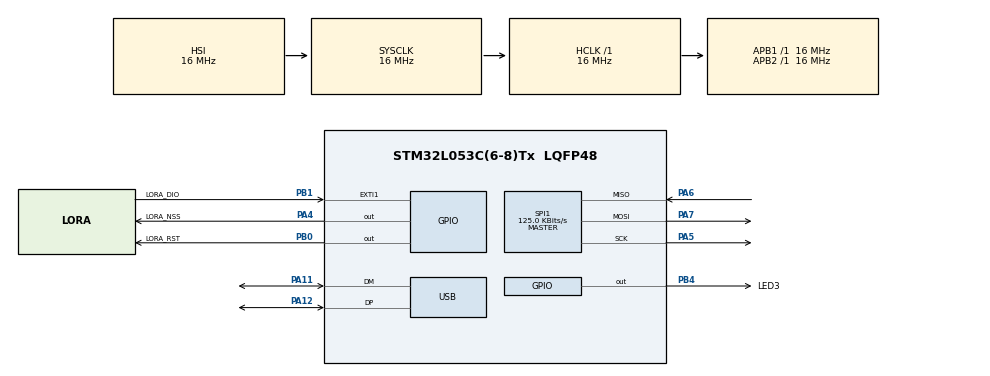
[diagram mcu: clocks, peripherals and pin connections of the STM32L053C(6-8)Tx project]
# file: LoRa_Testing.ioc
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Mcu.Family=STM32L0
Mcu.Name=STM32L053C(6-8)Tx
Mcu.Package=LQFP48
NVIC.EXTI0_1_IRQn=true\:0\:0\:false\:false\:true\:true\:true
NVIC.USB_IRQn=true\:0\:0\:false\:false\:true\:true\:true
PA11.Mode=Device
PA11.Signal=USB_DM
PA12.Mode=Device
PA12.Signal=USB_DP
PA4.GPIO_Label=LORA_NSS
PA4.PinState=GPIO_PIN_SET
PA4.Signal=GPIO_Output
PA5.Mode=Full_Duplex_Master
PA5.Signal=SPI1_SCK
PA6.Mode=Full_Duplex_Master
PA6.Signal=SPI1_MISO
PA7.Mode=Full_Duplex_Master
PA7.Signal=SPI1_MOSI
PB0.GPIO_Label=LORA_RST
PB0.PinState=GPIO_PIN_SET
PB0.Signal=GPIO_Output
PB1.GPIO_Label=LORA_DIO
PB1.GPIO_ModeDefaultEXTI=GPIO_MODE_IT_RISING
PB1.Signal=GPXTI1
PB4.GPIO_Label=LED3
PB4.Signal=GPIO_Output
ProjectManager.HeapSize=0x200
ProjectManager.StackSize=0x400
ProjectManager.TargetToolchain=TrueSTUDIO
RCC.AHBFreq_Value=16000000
RCC.APB1Freq_Value=16000000
RCC.APB1TimFreq_Value=16000000
RCC.APB2Freq_Value=16000000
RCC.APB2TimFreq_Value=16000000
RCC.HCLKFreq_Value=16000000
RCC.HSE_VALUE=8000000
RCC.HSI16_VALUE=16000000
RCC.HSI48MClockSelection=RCC_USBCLKSOURCE_HSI48
RCC.HSI48_VALUE=48000000
RCC.HSI_VALUE=16000000
RCC.LSE_VALUE=32768
RCC.MSI_VALUE=2097000
RCC.PLLMUL=RCC_PLLMUL_6
RCC.SYSCLKFreq_VALUE=16000000
RCC.SYSCLKSource=RCC_SYSCLKSOURCE_HSI
RCC.VCOOutputFreq_Value=96000000
SPI1.BaudRatePrescaler=SPI_BAUDRATEPRESCALER_128
SPI1.CalculateBaudRate=125.0 KBits/s
SPI1.Direction=SPI_DIRECTION_2LINES
SPI1.Mode=SPI_MODE_MASTER
SPI1.VirtualType=VM_MASTER
USB_DEVICE.CLASS_NAME_FS=CDC
USB_DEVICE.VirtualMode=Cdc
USB_DEVICE.VirtualModeFS=Cdc_FS
VP_USB_DEVICE_VS_USB_DEVICE_CDC_FS.Mode=CDC_FS
board=custom

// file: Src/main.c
/* USER CODE BEGIN Header */
/**
  ******************************************************************************
  * @file           : main.c
  * @brief          : Main program body
  ******************************************************************************
  * @attention
  *
  * <h2><center>&copy; Copyright (c) 2020 STMicroelectronics.
  * All rights reserved.</center></h2>
  *
  * This software component is licensed by ST under BSD 3-Clause license,
  * the "License"; You may not use this file except in compliance with the
  * License. You may obtain a copy of the License at:
  *                        opensource.org/licenses/BSD-3-Clause
  *
  ******************************************************************************
  */
/* USER CODE END Header */

#include "main.h"
#include "usb_device.h"

/* USER CODE BEGIN Includes */
#include "lora.h"
/* USER CODE END Includes */

SPI_HandleTypeDef hspi1;

extern uint8_t receive[80];

void SystemClock_Config(void);
static void MX_GPIO_Init(void);
static void MX_SPI1_Init(void);

/* USER CODE BEGIN 0 */
//uint8_t send[] = "Hello Jacob";

/* USER CODE END 0 */

int main(void)
{

  /* MCU Configuration--------------------------------------------------------*/

  /* Reset of all peripherals, Initializes the Flash interface and the Systick. */
  HAL_Init();

  /* Configure the system clock */
  SystemClock_Config();

  /* Initialize all configured peripherals */
  MX_GPIO_Init();
  MX_SPI1_Init();
  MX_USB_DEVICE_Init();
  /* USER CODE BEGIN 2 */

  LORA_INIT();

  /*
  sendPacket(send, sizeof(send));
  HAL_Delay(1000);
  sendPacket(send1, sizeof(send1));
  HAL_Delay(1000);
  sendPacket(send2, sizeof(send2));
  HAL_Delay(1000);
  sendPacket(send3, sizeof(send3));
  HAL_Delay(1000);
  */

  /* USER CODE END 2 */

  /* Infinite loop */
  /* USER CODE BEGIN WHILE */
  while (1)
  {
	  uint8_t test[] = "x,1,100,100,1000,NW\r\n";
	  sendPacket(test,sizeof(test));
	  HAL_Delay(1000);

	  /*
	  if(readReg(RH_RF95_REG_12_IRQ_FLAGS) == 0x50)
	  {
		  writeReg(RH_RF95_REG_01_OP_MODE, 0x01);
		  writeReg(RH_RF95_REG_12_IRQ_FLAGS, 0xFF);

		  receiveData();

		  writeReg(RH_RF95_REG_01_OP_MODE, 0x05);
		  writeReg(RH_RF95_REG_40_DIO_MAPPING1, 0x00);

		  HAL_GPIO_WritePin(LED3_GPIO_Port, LED3_Pin, GPIO_PIN_SET);
		  HAL_Delay(100);
		  HAL_GPIO_WritePin(LED3_GPIO_Port, LED3_Pin, GPIO_PIN_RESET);
	  }
	*/

    /* USER CODE END WHILE */

  }
}

void SystemClock_Config(void)
{
  RCC_OscInitTypeDef RCC_OscInitStruct = {0};
  RCC_ClkInitTypeDef RCC_ClkInitStruct = {0};
  RCC_PeriphCLKInitTypeDef PeriphClkInit = {0};

  /** Configure the main internal regulator output voltage
  */
  __HAL_PWR_VOLTAGESCALING_CONFIG(PWR_REGULATOR_VOLTAGE_SCALE1);
  /** Initializes the CPU, AHB and APB busses clocks
  */
  RCC_OscInitStruct.OscillatorType = RCC_OSCILLATORTYPE_HSI|RCC_OSCILLATORTYPE_HSI48;
  RCC_OscInitStruct.HSIState = RCC_HSI_ON;
  RCC_OscInitStruct.HSICalibrationValue = RCC_HSICALIBRATION_DEFAULT;
  RCC_OscInitStruct.HSI48State = RCC_HSI48_ON;
  RCC_OscInitStruct.PLL.PLLState = RCC_PLL_NONE;
  if (HAL_RCC_OscConfig(&RCC_OscInitStruct) != HAL_OK)
  {
    Error_Handler();
  }
  /** Initializes the CPU, AHB and APB busses clocks
  */
  RCC_ClkInitStruct.ClockType = RCC_CLOCKTYPE_HCLK|RCC_CLOCKTYPE_SYSCLK
                              |RCC_CLOCKTYPE_PCLK1|RCC_CLOCKTYPE_PCLK2;
  RCC_ClkInitStruct.SYSCLKSource = RCC_SYSCLKSOURCE_HSI;
  RCC_ClkInitStruct.AHBCLKDivider = RCC_SYSCLK_DIV1;
  RCC_ClkInitStruct.APB1CLKDivider = RCC_HCLK_DIV1;
  RCC_ClkInitStruct.APB2CLKDivider = RCC_HCLK_DIV1;

  if (HAL_RCC_ClockConfig(&RCC_ClkInitStruct, FLASH_LATENCY_0) != HAL_OK)
  {
    Error_Handler();
  }
  PeriphClkInit.PeriphClockSelection = RCC_PERIPHCLK_USB;
  PeriphClkInit.UsbClockSelection = RCC_USBCLKSOURCE_HSI48;
  if (HAL_RCCEx_PeriphCLKConfig(&PeriphClkInit) != HAL_OK)
  {
    Error_Handler();
  }
}

static void MX_SPI1_Init(void)
{

  /* SPI1 parameter configuration*/
  hspi1.Instance = SPI1;
  hspi1.Init.Mode = SPI_MODE_MASTER;
  hspi1.Init.Direction = SPI_DIRECTION_2LINES;
  hspi1.Init.DataSize = SPI_DATASIZE_8BIT;
  hspi1.Init.CLKPolarity = SPI_POLARITY_LOW;
  hspi1.Init.CLKPhase = SPI_PHASE_1EDGE;
  hspi1.Init.NSS = SPI_NSS_SOFT;
  hspi1.Init.BaudRatePrescaler = SPI_BAUDRATEPRESCALER_128;
  hspi1.Init.FirstBit = SPI_FIRSTBIT_MSB;
  hspi1.Init.TIMode = SPI_TIMODE_DISABLE;
  hspi1.Init.CRCCalculation = SPI_CRCCALCULATION_DISABLE;
  hspi1.Init.CRCPolynomial = 7;
  if (HAL_SPI_Init(&hspi1) != HAL_OK)
  {
    Error_Handler();
  }

}

static void MX_GPIO_Init(void)
{
  GPIO_InitTypeDef GPIO_InitStruct = {0};

  /* GPIO Ports Clock Enable */
  __HAL_RCC_GPIOA_CLK_ENABLE();
  __HAL_RCC_GPIOB_CLK_ENABLE();

  /*Configure GPIO pin Output Level */
  HAL_GPIO_WritePin(LORA_NSS_GPIO_Port, LORA_NSS_Pin, GPIO_PIN_SET);

  /*Configure GPIO pin Output Level */
  HAL_GPIO_WritePin(LORA_RST_GPIO_Port, LORA_RST_Pin, GPIO_PIN_SET);

  /*Configure GPIO pin Output Level */
  HAL_GPIO_WritePin(LED3_GPIO_Port, LED3_Pin, GPIO_PIN_RESET);

  /*Configure GPIO pin : LORA_NSS_Pin */
  GPIO_InitStruct.Pin = LORA_NSS_Pin;
  GPIO_InitStruct.Mode = GPIO_MODE_OUTPUT_PP;
  GPIO_InitStruct.Pull = GPIO_NOPULL;
  GPIO_InitStruct.Speed = GPIO_SPEED_FREQ_LOW;
  HAL_GPIO_Init(LORA_NSS_GPIO_Port, &GPIO_InitStruct);

  /*Configure GPIO pins : LORA_RST_Pin LED3_Pin */
  GPIO_InitStruct.Pin = LORA_RST_Pin|LED3_Pin;
  GPIO_InitStruct.Mode = GPIO_MODE_OUTPUT_PP;
  GPIO_InitStruct.Pull = GPIO_NOPULL;
  GPIO_InitStruct.Speed = GPIO_SPEED_FREQ_LOW;
  HAL_GPIO_Init(GPIOB, &GPIO_InitStruct);

  /*Configure GPIO pin : LORA_DIO_Pin */
  GPIO_InitStruct.Pin = LORA_DIO_Pin;
  GPIO_InitStruct.Mode = GPIO_MODE_IT_RISING;
  GPIO_InitStruct.Pull = GPIO_NOPULL;
  HAL_GPIO_Init(LORA_DIO_GPIO_Port, &GPIO_InitStruct);

  /* EXTI interrupt init*/
  HAL_NVIC_SetPriority(EXTI0_1_IRQn, 0, 0);
  HAL_NVIC_EnableIRQ(EXTI0_1_IRQn);

}

/* USER CODE BEGIN 4 */
void HAL_GPIO_EXTI_Callback(uint16_t GPIO_Pin){

	HAL_NVIC_DisableIRQ(EXTI0_1_IRQn);

	if(readReg(RH_RF95_REG_12_IRQ_FLAGS) == 0x50)
	  {
		  receiveData();
		  CDC_Transmit_FS(receive, sizeof(receive));

		  //HAL_GPIO_WritePin(LED3_GPIO_Port, LED3_Pin, GPIO_PIN_SET);
		  //HAL_Delay(100);
		  //HAL_GPIO_WritePin(LED3_GPIO_Port, LED3_Pin, GPIO_PIN_RESET);
	  }

	HAL_NVIC_EnableIRQ(EXTI0_1_IRQn);

}
/* USER CODE END 4 */

void Error_Handler(void)
{
}

/************************ (C) COPYRIGHT STMicroelectronics *****END OF FILE****/
